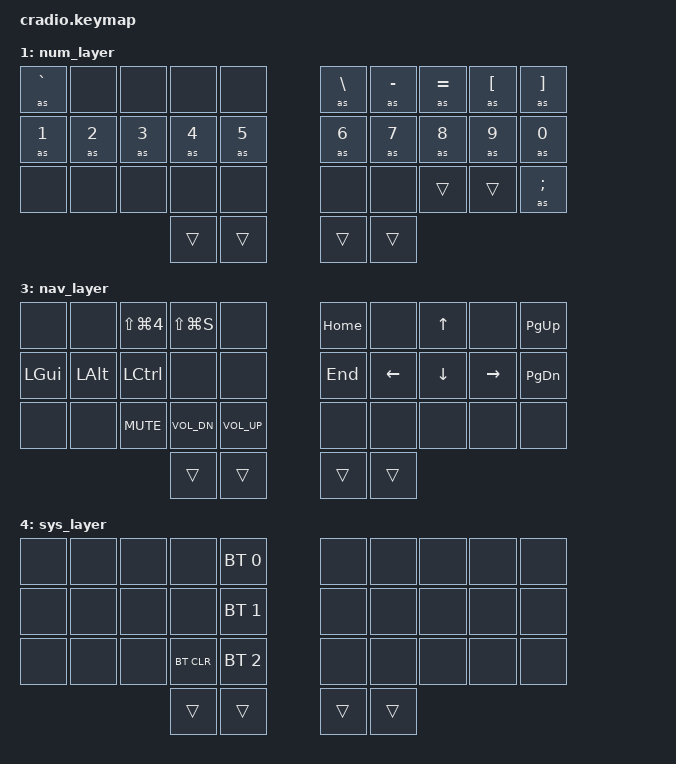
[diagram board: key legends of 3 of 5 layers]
// Copyright (c) 2022 The ZMK Contributors
// SPDX-License-Identifier: MIT

#include <behaviors.dtsi>
#include <dt-bindings/zmk/keys.h>
#include <dt-bindings/zmk/bt.h>

// Home row mods macro
#define HRML(k1,k2,k3) &ht LGUI k1  &ht LALT k2  &ht LCTRL k3 
#define HRMR(k1,k2,k3) &ht RCTRL k1 &ht LALT k2  &ht RGUI k3  

/ {
    behaviors {
        ht: hold_tap {
            compatible = "zmk,behavior-hold-tap";
            #binding-cells = <2>;
            flavor = "balanced";
            tapping-term-ms = <200>;
            quick-tap-ms = <200>;
            require-prior-idle-ms = <125>;
            bindings = <&kp>, <&kp>;
        };
        as_ht: autoshift_hold_tap {
            compatible = "zmk,behavior-hold-tap";
            label = "AUTOSHIFT_HOLD_TAP";
            #binding-cells = <2>;
            tapping-term-ms = <200>;
            bindings = <&shifted>, <&kp>;
            flavor = "tap-preferred";
        };
        combos {
            compatible = "zmk,combos";
            combo_esc {
                timeout-ms = <50>;
                key-positions = <0 1>;
                bindings = <&kp ESC>;
            };
            combo_del {
                timeout-ms = <50>;
                key-positions = <8 9>;
                bindings = <&kp DEL>;
            };
            combo_reset {
                timeout-ms = <50>;
                key-positions = <0 9>;
                layers = <4>;
                bindings = <&sys_reset>;
            };
            combo_boot {
                timeout-ms = <50>;
                key-positions = <10 19>;
                layers = <4>;
                bindings = <&bootloader>;
            };
        };
    };

    macros {
    shifted: macro_shifted_kp {
      #binding-cells = <1>;
      label = "MACRO_SHIFTED_KP";
      compatible = "zmk,behavior-macro-one-param";
      bindings =
        <&macro_press &kp LSHFT>,
        <&macro_param_1to1 &macro_tap &kp MACRO_PLACEHOLDER>,
        <&macro_release &kp LSHFT>;
    };

    as: autoshift {
      compatible = "zmk,behavior-macro-one-param";
      #binding-cells = <1>;
      label = "AUTOSHIFT_KP";
      bindings =
        <&macro_press>,
        <&macro_param_1to1>,
        <&macro_param_1to2>,
        <&as_ht MACRO_PLACEHOLDER MACRO_PLACEHOLDER>,
        <&macro_pause_for_release>,
        <&macro_release>,
        <&macro_param_1to1>,
        <&macro_param_1to2>,
        <&as_ht MACRO_PLACEHOLDER MACRO_PLACEHOLDER>;
    };
  };

    conditional_layers {
        compatible = "zmk,conditional-layers";
        tri_layer {
            if-layers = <2 3>;
            then-layer = <4>;
        };
    };

    keymap {
        compatible = "zmk,keymap";
        default_layer {
            bindings = <
        //╭──────────┬──────────┬──────────┬──────────┬──────────╮      ╭──────────┬──────────┬──────────┬──────────┬──────────╮
        //│  Q       │  W       │  F       │  P       │  B       │      │  J       │  L       │  U       │  Y       │ ' "      │
            &kp Q      &kp W      &kp F      &kp P      &kp B             &kp J      &kp L      &kp U      &kp Y      &as SQT
        //├──────────┼──────────┼──────────┼──────────┼──────────┤      ├──────────┼──────────┼──────────┼──────────┼──────────┤
        //│  A       │  R       │  S       │  T       │  G       │      │  M       │  N       │  E       │  I       │ O        │
            HRML(A,     R,         S)         &kp T     &kp G             &kp M      &kp N      HRMR(E,     I,        O)
        //├──────────┼──────────┼──────────┼──────────┼──────────┤      ├──────────┼──────────┼──────────┼──────────┼──────────┤
        //│  Z       │  X       │  C       │  D       │  V       │      │  K       │  H       │ , <      │ . >      │ / ?      │
            &kp Z      &kp X      &kp C      &kp D      &kp V             &kp K      &kp H      &as COMMA  &as DOT    &as FSLH
        //╰──────────┴──────────┴──────────┼──────────┼──────────┤      ├──────────┼──────────┼──────────┴──────────┴──────────╯
                                            &lt 3 TAB  &mt LSHIFT BSPC   &lt 1 SPACE &lt 2 RET
        //                                 ╰──────────┴──────────╯      ╰──────────┴──────────╯
            >;
        };

        num_layer {
            bindings = <
        //╭──────────┬──────────┬──────────┬──────────┬──────────╮   ╭──────────┬──────────┬──────────┬──────────┬──────────╮
        //│  ` ~     │          │          │          │          │   │  \ |     │  - _     │  = +     │  [ {     │  ] }     │
            &as GRAVE  &none      &none      &none      &none          &as BSLH   &as MINUS  &as EQUAL  &as LBKT   &as RBKT
        //├──────────┼──────────┼──────────┼──────────┼──────────┤   ├──────────┼──────────┼──────────┼──────────┼──────────┤
        //│  1 !     │  2 @     │  3 #     │  4 $     │  5 %     │   │  6 ^     │  7 &     │  8 *     │  9 (     │  0 )     │
            &as N1     &as N2     &as N3     &as N4     &as N5         &as N6     &as N7     &as N8     &as N9     &as N0    
        //├──────────┼──────────┼──────────┼──────────┼──────────┤   ├──────────┼──────────┼──────────┼──────────┼──────────┤
        //│          │          │          │          │          │   │          │          │          │          │          │
            &none      &none      &none      &none      &none          &none      &none      &trans     &trans     &as SEMI
        //╰──────────┴──────────┴──────────┼──────────┼──────────┤   ├──────────┼──────────┼──────────┴──────────┴──────────╯
                                             &trans     &trans         &trans     &trans
        //                                 ╰──────────┴──────────╯   ╰──────────┴──────────╯
            >;
        };

        fn_layer {
            bindings = <
        //╭──────────┬──────────┬──────────┬──────────┬──────────╮   ╭──────────┬──────────┬──────────┬──────────┬──────────╮
        //│          │          │          │          │          │   │          │          │          │  F11     │  F12     │
            &none      &none      &none      &none      &none          &none      &none      &none      &kp F11    &kp F12
        //├──────────┼──────────┼──────────┼──────────┼──────────┤   ├──────────┼──────────┼──────────┼──────────┼──────────┤
        //│  F1      │  F2      │  F3      │  F4      │  F5      │   │  F6      │  F7      │  F8      │  F9      │  F10     │
            HRML(F1,    F2,        F3)       &kp F4     &kp F5         &kp F6     &kp F7     HRMR(F8,    F9,        F10)  
        //├──────────┼──────────┼──────────┼──────────┼──────────┤   ├──────────┼──────────┼──────────┼──────────┼──────────┤
        //│          │          │          │          │          │   │          │          │          │          │          │
            &none      &none      &none      &none      &none          &none      &none      &none      &none      &none 
        //╰──────────┴──────────┴──────────┼──────────┼──────────┤   ├──────────┼──────────┼──────────┴──────────┴──────────╯
                                             &trans     &trans         &trans     &trans
        //                                 ╰──────────┴──────────╯   ╰──────────┴──────────╯
            >;
        };

        nav_layer {
            bindings = <
        //╭──────────┬──────────┬──────────┬──────────┬──────────╮   ╭──────────┬──────────┬──────────┬──────────┬──────────╮
        //│          │          │          │          │          │   │  HOME    │          │  UP      │          │  PG_UP   │
            &none      &none  &kp LS(LG(N4)) &kp LS(LG(S)) &none      &kp HOME   &none      &kp UP     &none      &kp PG_UP
        //├──────────┼──────────┼──────────┼──────────┼──────────┤   ├──────────┼──────────┼──────────┼──────────┼──────────┤
        //│  LGUI    │  LALT    │  LCTRL   │          │          │   │  END     │  LEFT    │  DOWN    │  RIGHT   │  PG_DN   │
            &kp LGUI   &kp LALT   &kp LCTRL  &none      &none          &kp END    &kp LEFT   &kp DOWN  &kp RIGHT  &kp PG_DN
        //├──────────┼──────────┼──────────┼──────────┼──────────┤   ├──────────┼──────────┼──────────┼──────────┼──────────┤
        //│          │          │          │          │          │   │          │          │          │          │          │
            &none      &none      &kp C_MUTE &kp C_VOL_DN &kp C_VOL_UP &none      &none      &none      &none      &none
        //╰──────────┴──────────┴──────────┼──────────┼──────────┤   ├──────────┼──────────┼──────────┴──────────┴──────────╯
                                             &trans     &trans         &trans     &trans
        //                                 ╰──────────┴──────────╯   ╰──────────┴──────────╯
            >;
        };

        sys_layer {
            bindings = <
        //╭──────────┬──────────┬──────────┬──────────┬──────────╮   ╭──────────┬──────────┬──────────┬──────────┬──────────╮
        //│          │          │          │          │PROFILE 0 │   │          │          │          │          │          │
            &none      &none      &none      &none     &bt BT_SEL 0    &none      &none      &none      &none      &none 
        //├──────────┼──────────┼──────────┼──────────┼──────────┤   ├──────────┼──────────┼──────────┼──────────┼──────────┤
        //│          │          │          │          │PROFILE 1 │   │          │          │          │          │          │
            &none      &none      &none      &none     &bt BT_SEL 1    &none      &none      &none      &none      &none   
        //├──────────┼──────────┼──────────┼──────────┼──────────┤   ├──────────┼──────────┼──────────┼──────────┼──────────┤
        //│          │          │          │ CLEAR BT │PROFILE 2 │   │          │          │          │          │          │
            &none      &none      &none     &bt BT_CLR &bt BT_SEL 2    &none      &none      &none      &none      &none
        //╰──────────┴──────────┴──────────┼──────────┼──────────┤   ├──────────┼──────────┼──────────┴──────────┴──────────╯
                                             &trans     &trans         &trans     &trans
        //                                 ╰──────────┴──────────╯   ╰──────────┴──────────╯
            >;
        };
    };
};
